# epi register map
Vendor: Texas Instruments
Peripheral module from a debugger description file (folder sc4ce290ncpz).
Registers are 32-bit, read-write, no defined reset value unless marked. A register's access mark holds for its fields unless they carry their own. Offsets are as the file gives them; lines under a group give offsets from that group; [hi:lo] are bit positions; {n}, {i} and the like mark numbered series; 'fields as' and 'values as' point back to an identical list; <NAME> marks a mode.

## EPI0 — External Peripheral Interface register offsets
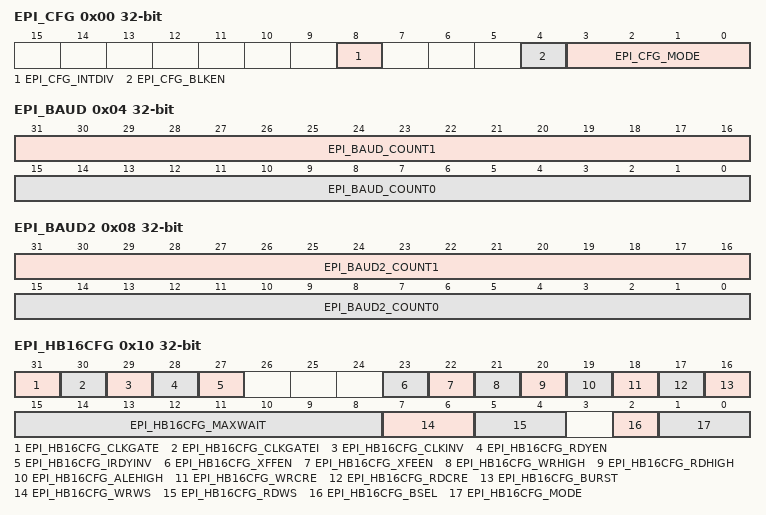
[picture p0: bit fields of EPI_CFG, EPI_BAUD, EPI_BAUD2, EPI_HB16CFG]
0x00 EPI_CFG — EPI Configuration
  [8] EPI_CFG_INTDIV — Integer Clock Divider Enable
  [4] EPI_CFG_BLKEN — Block Enable
  [3:0] EPI_CFG_MODE — Mode Select
    0=EPI_CFG_MODE_NONE (General Purpose); 1=EPI_CFG_MODE_SDRAM (SDRAM); 2=EPI_CFG_MODE_HB8 (8-Bit Host-Bus (HB8)); 3=EPI_CFG_MODE_HB16 (16-Bit Host-Bus (HB16))
0x04 EPI_BAUD — EPI Main Baud Rate
  [31:16] EPI_BAUD_COUNT1 — Baud Rate Counter 1
  [15:0] EPI_BAUD_COUNT0 — Baud Rate Counter 0
0x08 EPI_BAUD2 — EPI Main Baud Rate
  [31:16] EPI_BAUD2_COUNT1 — CS3n Baud Rate Counter 1
  [15:0] EPI_BAUD2_COUNT0 — CS2n Baud Rate Counter 0
0x10 EPI_HB16CFG — EPI Host-Bus 16 Configuration
  [31] EPI_HB16CFG_CLKGATE — Clock Gated
  [30] EPI_HB16CFG_CLKGATEI — Clock Gated Idle
  [29] EPI_HB16CFG_CLKINV — Invert Output Clock Enable
  [28] EPI_HB16CFG_RDYEN — Input Ready Enable
  [27] EPI_HB16CFG_IRDYINV — Input Ready Invert
  [23] EPI_HB16CFG_XFFEN — External FIFO FULL Enable
  [22] EPI_HB16CFG_XFEEN — External FIFO EMPTY Enable
  [21] EPI_HB16CFG_WRHIGH — WRITE Strobe Polarity
  [20] EPI_HB16CFG_RDHIGH — READ Strobe Polarity
  [19] EPI_HB16CFG_ALEHIGH — ALE Strobe Polarity
  [18] EPI_HB16CFG_WRCRE — PSRAM Configuration Register Write
  [17] EPI_HB16CFG_RDCRE — PSRAM Configuration Register Read
  [16] EPI_HB16CFG_BURST — Burst Mode
  [15:8] EPI_HB16CFG_MAXWAIT — Maximum Wait
  [7:6] EPI_HB16CFG_WRWS — Write Wait States
    0=Active WRn is 2 EPI clocks; 1=Active WRn is 4 EPI clocks; 2=Active WRn is 6 EPI clocks; 3=Active WRn is 8 EPI clocks
  [5:4] EPI_HB16CFG_RDWS — Read Wait States
    0=Active RDn is 2 EPI clocks; 1=Active RDn is 4 EPI clocks; 2=Active RDn is 6 EPI clocks; 3=Active RDn is 8 EPI clocks
  [2] EPI_HB16CFG_BSEL — Byte Select Configuration
  [1:0] EPI_HB16CFG_MODE — Host Bus Sub-Mode
    0=EPI_HB16CFG_MODE_ADMUX (ADMUX - AD[15:0]); 1=EPI_HB16CFG_MODE_ADNMUX (ADNONMUX - D[15:0]); 2=EPI_HB16CFG_MODE_SRAM (Continuous Read - D[15:0]); 3=EPI_HB16CFG_MODE_XFIFO (XFIFO - D[15:0])
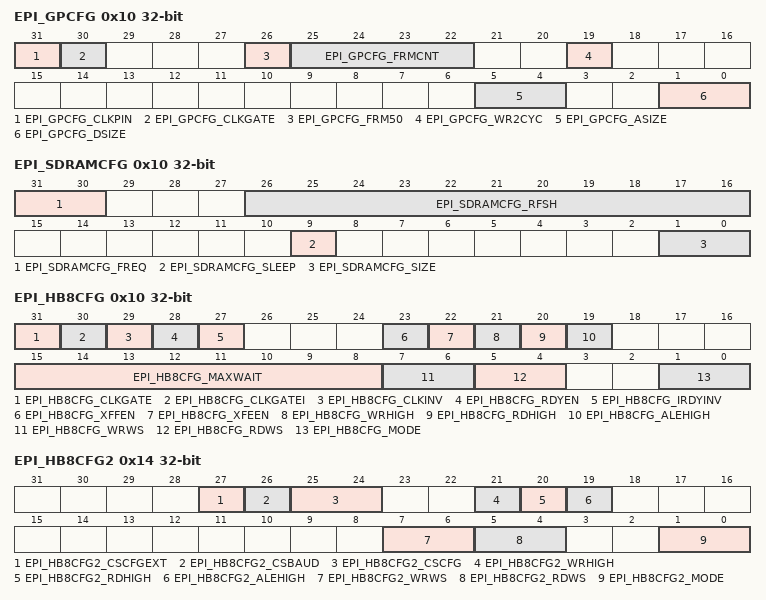
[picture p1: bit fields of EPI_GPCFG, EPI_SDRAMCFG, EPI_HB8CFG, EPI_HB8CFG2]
0x10 EPI_GPCFG — EPI General-Purpose Configuration
  [31] EPI_GPCFG_CLKPIN — Clock Pin
  [30] EPI_GPCFG_CLKGATE — Clock Gated
  [26] EPI_GPCFG_FRM50 — 50/50 Frame
  [25:22] EPI_GPCFG_FRMCNT — Frame Count
  [19] EPI_GPCFG_WR2CYC — 2-Cycle Writes
  [5:4] EPI_GPCFG_ASIZE — Address Bus Size
    0=EPI_GPCFG_ASIZE_NONE (No address); 1=EPI_GPCFG_ASIZE_4BIT (Up to 4 bits wide); 2=EPI_GPCFG_ASIZE_12BIT (Up to 12 bits wide. This size cannot be used with 24-bit data); 3=EPI_GPCFG_ASIZE_20BIT (Up to 20 bits wide. This size cannot be used with data sizes other than 8)
  [1:0] EPI_GPCFG_DSIZE — Size of Data Bus
    0=EPI_GPCFG_DSIZE_4BIT (8 Bits Wide (EPI0S0 to EPI0S7)); 1=EPI_GPCFG_DSIZE_16BIT (16 Bits Wide (EPI0S0 to EPI0S15)); 2=EPI_GPCFG_DSIZE_24BIT (24 Bits Wide (EPI0S0 to EPI0S23)); 3=EPI_GPCFG_DSIZE_32BIT (32 Bits Wide (EPI0S0 to EPI0S31))
0x10 EPI_SDRAMCFG — EPI SDRAM Configuration
  [31:30] EPI_SDRAMCFG_FREQ — EPI Frequency Range
    0=EPI_SDRAMCFG_FREQ_NONE (0 - 15 MHz); 1=EPI_SDRAMCFG_FREQ_15MHZ (15 - 30 MHz); 2=EPI_SDRAMCFG_FREQ_30MHZ (30 - 50 MHz)
  [26:16] EPI_SDRAMCFG_RFSH — Refresh Counter
  [9] EPI_SDRAMCFG_SLEEP — Sleep Mode
  [1:0] EPI_SDRAMCFG_SIZE — Size of SDRAM
    0=EPI_SDRAMCFG_SIZE_8MB (64 megabits (8MB)); 1=EPI_SDRAMCFG_SIZE_16MB (128 megabits (16MB)); 2=EPI_SDRAMCFG_SIZE_32MB (256 megabits (32MB)); 3=EPI_SDRAMCFG_SIZE_64MB (512 megabits (64MB))
0x10 EPI_HB8CFG — EPI Host-Bus 8 Configuration
  [31] EPI_HB8CFG_CLKGATE — Clock Gated
  [30] EPI_HB8CFG_CLKGATEI — Clock Gated when Idle
  [29] EPI_HB8CFG_CLKINV — Invert Output Clock Enable
  [28] EPI_HB8CFG_RDYEN — Input Ready Enable
  [27] EPI_HB8CFG_IRDYINV — Input Ready Invert
  [23] EPI_HB8CFG_XFFEN — External FIFO FULL Enable
  [22] EPI_HB8CFG_XFEEN — External FIFO EMPTY Enable
  [21] EPI_HB8CFG_WRHIGH — WRITE Strobe Polarity
  [20] EPI_HB8CFG_RDHIGH — READ Strobe Polarity
  [19] EPI_HB8CFG_ALEHIGH — ALE Strobe Polarity
  [15:8] EPI_HB8CFG_MAXWAIT — Maximum Wait
  [7:6] EPI_HB8CFG_WRWS — Write Wait States
    values as EPI_HB16CFG.EPI_HB16CFG_WRWS
  [5:4] EPI_HB8CFG_RDWS — Read Wait States
    values as EPI_HB16CFG.EPI_HB16CFG_RDWS
  [1:0] EPI_HB8CFG_MODE — Host Bus Sub-Mode
    0=EPI_HB8CFG_MODE_MUX (ADMUX - AD[7:0]); 1=EPI_HB8CFG_MODE_NMUX (ADNONMUX - D[7:0]); 2=EPI_HB8CFG_MODE_SRAM (Continuous Read - D[7:0]); 3=EPI_HB8CFG_MODE_FIFO (XFIFO - D[7:0])
0x14 EPI_HB8CFG2 — EPI Host-Bus 8 Configuration 2
  [27] EPI_HB8CFG2_CSCFGEXT — Chip Select Extended Configuration
  [26] EPI_HB8CFG2_CSBAUD — Chip Select Baud Rate and Multiple Sub-Mode Configuration enable
  [25:24] EPI_HB8CFG2_CSCFG — Chip Select Configuration
    0=EPI_HB8CFG2_CSCFG_ALE (ALE Configuration); 1=EPI_HB8CFG2_CSCFG_CS (CSn Configuration); 2=EPI_HB8CFG2_CSCFG_DCS (Dual CSn Configuration); 3=EPI_HB8CFG2_CSCFG_ADCS (ALE with Dual CSn Configuration)
  [21] EPI_HB8CFG2_WRHIGH — CS1n WRITE Strobe Polarity
  [20] EPI_HB8CFG2_RDHIGH — CS1n READ Strobe Polarity
  [19] EPI_HB8CFG2_ALEHIGH — CS1n ALE Strobe Polarity
  [7:6] EPI_HB8CFG2_WRWS — CS1n Write Wait States
    values as EPI_HB16CFG.EPI_HB16CFG_WRWS
  [5:4] EPI_HB8CFG2_RDWS — CS1n Read Wait States
    values as EPI_HB16CFG.EPI_HB16CFG_RDWS
  [1:0] EPI_HB8CFG2_MODE — CS1n Host Bus Sub-Mode
    0=EPI_HB8CFG2_MODE_ADMUX (ADMUX - AD[7:0]); 1=EPI_HB8CFG2_MODE_AD (ADNONMUX - D[7:0])
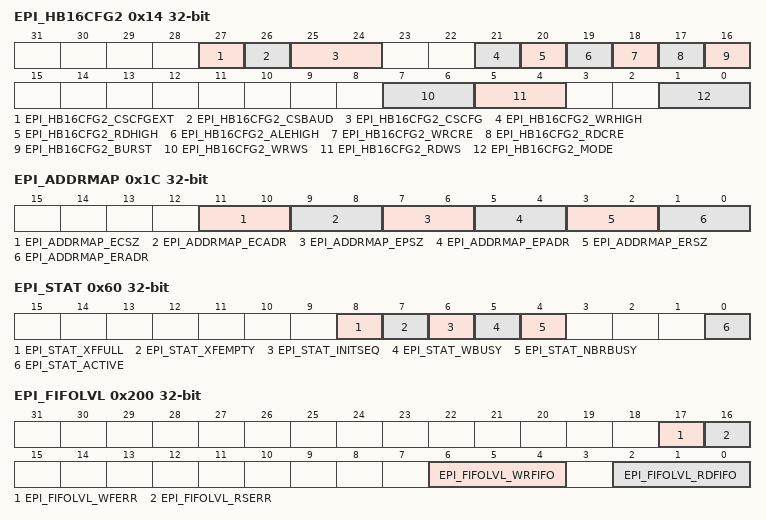
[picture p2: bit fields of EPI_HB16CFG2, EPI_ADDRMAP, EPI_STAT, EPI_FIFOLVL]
0x14 EPI_HB16CFG2 — EPI Host-Bus 16 Configuration 2
  [27] EPI_HB16CFG2_CSCFGEXT — Chip Select Extended Configuration
  [26] EPI_HB16CFG2_CSBAUD — Chip Select Baud Rate and Multiple Sub-Mode Configuration enable
  [25:24] EPI_HB16CFG2_CSCFG — Chip Select Configuration
    0=EPI_HB16CFG2_CSCFG_ALE (ALE Configuration); 1=EPI_HB16CFG2_CSCFG_CS (CSn Configuration); 2=EPI_HB16CFG2_CSCFG_DCS (Dual CSn Configuration); 3=EPI_HB16CFG2_CSCFG_ADCS (ALE with Dual CSn Configuration)
  [21] EPI_HB16CFG2_WRHIGH — CS1n WRITE Strobe Polarity
  [20] EPI_HB16CFG2_RDHIGH — CS1n READ Strobe Polarity
  [19] EPI_HB16CFG2_ALEHIGH — CS1n ALE Strobe Polarity
  [18] EPI_HB16CFG2_WRCRE — CS1n PSRAM Configuration Register Write
  [17] EPI_HB16CFG2_RDCRE — CS1n PSRAM Configuration Register Read
  [16] EPI_HB16CFG2_BURST — CS1n Burst Mode
  [7:6] EPI_HB16CFG2_WRWS — CS1n Write Wait States
    values as EPI_HB16CFG.EPI_HB16CFG_WRWS
  [5:4] EPI_HB16CFG2_RDWS — CS1n Read Wait States
    values as EPI_HB16CFG.EPI_HB16CFG_RDWS
  [1:0] EPI_HB16CFG2_MODE — CS1n Host Bus Sub-Mode
    0=EPI_HB16CFG2_MODE_ADMUX (ADMUX - AD[15:0]); 1=EPI_HB16CFG2_MODE_AD (ADNONMUX - D[15:0])
0x1C EPI_ADDRMAP — EPI Address Map
  [11:10] EPI_ADDRMAP_ECSZ — External Code Size
    0=EPI_ADDRMAP_ECSZ_256B (256 bytes; lower address range: 0x00 to 0xFF); 1=EPI_ADDRMAP_ECSZ_64KB (64 KB; lower address range: 0x0000 to 0xFFFF); 2=EPI_ADDRMAP_ECSZ_16MB (16 MB; lower address range: 0x00.0000 to 0xFF.FFFF); 3=EPI_ADDRMAP_ECSZ_256MB (256MB; lower address range: 0x000.0000 to 0x0FFF.FFFF)
  [9:8] EPI_ADDRMAP_ECADR — External Code Address
    0=EPI_ADDRMAP_ECADR_NONE (Not mapped); 1=At 0x1000.0000
  [7:6] EPI_ADDRMAP_EPSZ — External Peripheral Size
    0=EPI_ADDRMAP_EPSZ_256B (256 bytes; lower address range: 0x00 to 0xFF); 1=EPI_ADDRMAP_EPSZ_64KB (64 KB; lower address range: 0x0000 to 0xFFFF); 2=EPI_ADDRMAP_EPSZ_16MB (16 MB; lower address range: 0x00.0000 to 0xFF.FFFF); 3=EPI_ADDRMAP_EPSZ_256MB (256 MB; lower address range: 0x000.0000 to 0xFFF.FFFF)
  [5:4] EPI_ADDRMAP_EPADR — External Peripheral Address
    0=EPI_ADDRMAP_EPADR_NONE (Not mapped); 1=EPI_ADDRMAP_EPADR_A000 (At 0xA000.0000); 2=EPI_ADDRMAP_EPADR_C000 (At 0xC000.0000); 3=EPI_ADDRMAP_EPADR_HBQS (Only to be used with Host Bus quad chip select. In quad chip select mode, CS2n maps to 0xA000.0000 and CS3n maps to 0xC000.0000)
  [3:2] EPI_ADDRMAP_ERSZ — External RAM Size
    0=EPI_ADDRMAP_ERSZ_256B (256 bytes; lower address range: 0x00 to 0xFF); 1=EPI_ADDRMAP_ERSZ_64KB (64 KB; lower address range: 0x0000 to 0xFFFF); 2=EPI_ADDRMAP_ERSZ_16MB (16 MB; lower address range: 0x00.0000 to 0xFF.FFFF); 3=EPI_ADDRMAP_ERSZ_256MB (256 MB; lower address range: 0x000.0000 to 0xFFF.FFFF)
  [1:0] EPI_ADDRMAP_ERADR — External RAM Address
    0=EPI_ADDRMAP_ERADR_NONE (Not mapped); 1=At 0x6000.0000; 2=At 0x8000.0000; 3=EPI_ADDRMAP_ERADR_HBQS (Only to be used with Host Bus quad chip select. In quad chip select mode, CS0n maps to 0x6000.0000 and CS1n maps to 0x8000.0000)
0x20 EPI_RSIZE0 — EPI Read Size 0
  [1:0] EPI_RSIZE0_SIZE — Current Size
    1=EPI_RSIZE0_SIZE_8BIT (Byte (8 bits)); 2=EPI_RSIZE0_SIZE_16BIT (Half-word (16 bits)); 3=EPI_RSIZE0_SIZE_32BIT (Word (32 bits))
0x24 EPI_RADDR0 — EPI Read Address 0
  [31:0] EPI_RADDR0_ADDR — Current Address
0x28 EPI_RPSTD0 — EPI Non-Blocking Read Data 0
  [12:0] EPI_RPSTD0_POSTCNT — Post Count
0x30 EPI_RSIZE1 — EPI Read Size 1
  [1:0] EPI_RSIZE1_SIZE — Current Size
    1=EPI_RSIZE1_SIZE_8BIT (Byte (8 bits)); 2=EPI_RSIZE1_SIZE_16BIT (Half-word (16 bits)); 3=EPI_RSIZE1_SIZE_32BIT (Word (32 bits))
0x34 EPI_RADDR1 — EPI Read Address 1
  [31:0] EPI_RADDR1_ADDR — Current Address
0x38 EPI_RPSTD1 — EPI Non-Blocking Read Data 1
  [12:0] EPI_RPSTD1_POSTCNT — Post Count
0x60 EPI_STAT ro — EPI Status
  [8] EPI_STAT_XFFULL — External FIFO Full
  [7] EPI_STAT_XFEMPTY — External FIFO Empty
  [6] EPI_STAT_INITSEQ — Initialization Sequence
  [5] EPI_STAT_WBUSY — Write Busy
  [4] EPI_STAT_NBRBUSY — Non-Blocking Read Busy
  [0] EPI_STAT_ACTIVE — Register Active
0x6C EPI_RFIFOCNT ro — EPI Read FIFO Count
  [3:0] EPI_RFIFOCNT_COUNT — FIFO Count
0x70 EPI_READFIFO0 ro — EPI Read FIFO
  [31:0] EPI_READFIFO0_DATA — Reads Data
{0x70+4i} EPI_READFIFO{i} ro (i=1..7) — EPI Read FIFO Alias {i}
  [31:0] EPI_READFIFO{i}_DATA — Reads Data
0x200 EPI_FIFOLVL — EPI FIFO Level Selects
  [17] EPI_FIFOLVL_WFERR — Write Full Error
  [16] EPI_FIFOLVL_RSERR — Read Stall Error
  [6:4] EPI_FIFOLVL_WRFIFO — Write FIFO
    0=EPI_FIFOLVL_WRFIFO_EMPT (Interrupt is triggered while WRFIFO is empty.); 2=Interrupt is triggered until there are only two slots available. Thus, trigger is deasserted when there are two WRFIFO entries present. This configuration is optimized for bursts of 2; 3=Interrupt is triggered until there is one WRFIFO entry available. This configuration expects only single writes; 4=EPI_FIFOLVL_WRFIFO_NFULL (Trigger interrupt when WRFIFO is not full, meaning trigger will continue to assert until there are four entries in the WRFIFO)
  [2:0] EPI_FIFOLVL_RDFIFO — Read FIFO
    1=Trigger when there are 1 or more entries in the NBRFIFO; 2=Trigger when there are 2 or more entries in the NBRFIFO; 3=Trigger when there are 4 or more entries in the NBRFIFO; 4=Trigger when there are 6 or more entries in the NBRFIFO; 5=Trigger when there are 7 or more entries in the NBRFIFO; 6=Trigger when there are 8 entries in the NBRFIFO
0x204 EPI_WFIFOCNT ro — EPI Write FIFO Count
  [2:0] EPI_WFIFOCNT_WTAV — Available Write Transactions
0x208 EPI_DMATXCNT — EPI DMA Transmit Count
  [15:0] EPI_DMATXCNT_TXCNT — DMA Count
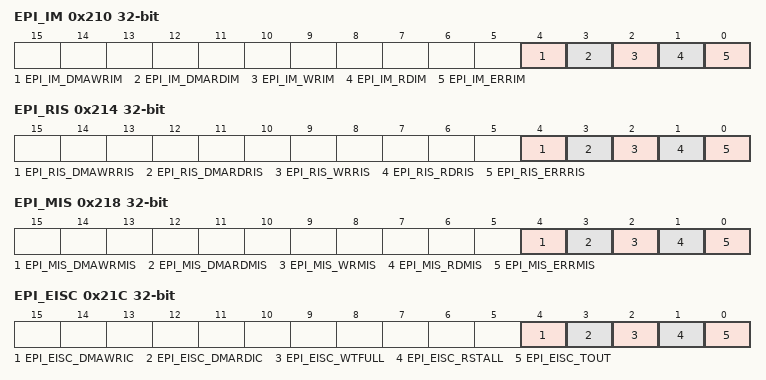
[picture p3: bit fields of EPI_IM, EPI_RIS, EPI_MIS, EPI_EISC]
0x210 EPI_IM — EPI Interrupt Mask
  [4] EPI_IM_DMAWRIM — Write uDMA Interrupt Mask
  [3] EPI_IM_DMARDIM — Read uDMA Interrupt Mask
  [2] EPI_IM_WRIM — Write FIFO Empty Interrupt Mask
  [1] EPI_IM_RDIM — Read FIFO Full Interrupt Mask
  [0] EPI_IM_ERRIM — Error Interrupt Mask
0x214 EPI_RIS ro — EPI Raw Interrupt Status
  [4] EPI_RIS_DMAWRRIS — Write uDMA Raw Interrupt Status
  [3] EPI_RIS_DMARDRIS — Read uDMA Raw Interrupt Status
  [2] EPI_RIS_WRRIS — Write Raw Interrupt Status
  [1] EPI_RIS_RDRIS — Read Raw Interrupt Status
  [0] EPI_RIS_ERRRIS — Error Raw Interrupt Status
0x218 EPI_MIS ro — EPI Masked Interrupt Status
  [4] EPI_MIS_DMAWRMIS — Write uDMA Masked Interrupt Status
  [3] EPI_MIS_DMARDMIS — Read uDMA Masked Interrupt Status
  [2] EPI_MIS_WRMIS — Write Masked Interrupt Status
  [1] EPI_MIS_RDMIS — Read Masked Interrupt Status
  [0] EPI_MIS_ERRMIS — Error Masked Interrupt Status
0x21C EPI_EISC — EPI Error and Interrupt Status and Clear
  [4] EPI_EISC_DMAWRIC — Write uDMA Interrupt Clear
  [3] EPI_EISC_DMARDIC — Read uDMA Interrupt Clear
  [2] EPI_EISC_WTFULL — Write FIFO Full Error
  [1] EPI_EISC_RSTALL — Read Stalled Error
  [0] EPI_EISC_TOUT — Timeout Error
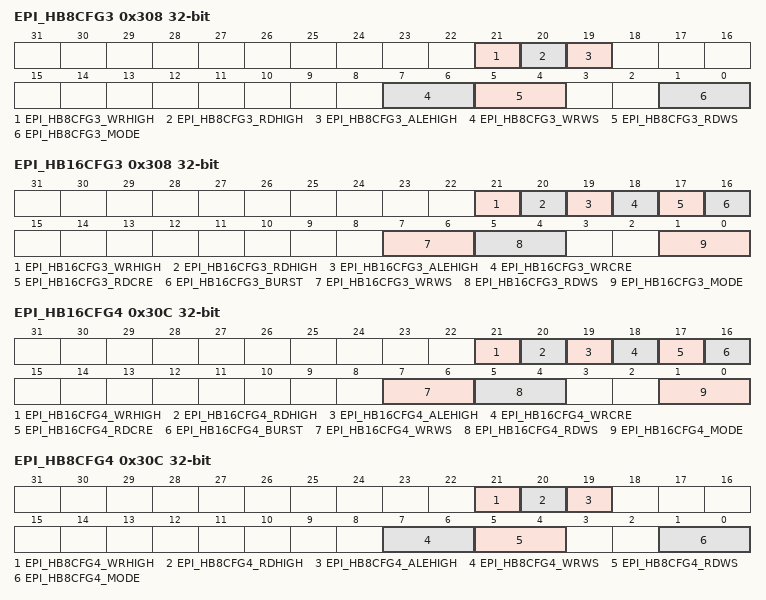
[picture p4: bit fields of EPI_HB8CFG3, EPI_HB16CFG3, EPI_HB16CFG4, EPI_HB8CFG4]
0x308 EPI_HB8CFG3 — EPI Host-Bus 8 Configuration 3
  [21] EPI_HB8CFG3_WRHIGH — CS2n WRITE Strobe Polarity
  [20] EPI_HB8CFG3_RDHIGH — CS2n READ Strobe Polarity
  [19] EPI_HB8CFG3_ALEHIGH — CS2n ALE Strobe Polarity
  [7:6] EPI_HB8CFG3_WRWS — CS2n Write Wait States
    values as EPI_HB16CFG.EPI_HB16CFG_WRWS
  [5:4] EPI_HB8CFG3_RDWS — CS2n Read Wait States
    values as EPI_HB16CFG.EPI_HB16CFG_RDWS
  [1:0] EPI_HB8CFG3_MODE — CS2n Host Bus Sub-Mode
    0=EPI_HB8CFG3_MODE_ADMUX (ADMUX - AD[7:0]); 1=EPI_HB8CFG3_MODE_AD (ADNONMUX - D[7:0])
0x308 EPI_HB16CFG3 — EPI Host-Bus 16 Configuration 3
  [21] EPI_HB16CFG3_WRHIGH — CS2n WRITE Strobe Polarity
  [20] EPI_HB16CFG3_RDHIGH — CS2n READ Strobe Polarity
  [19] EPI_HB16CFG3_ALEHIGH — CS2n ALE Strobe Polarity
  [18] EPI_HB16CFG3_WRCRE — CS2n PSRAM Configuration Register Write
  [17] EPI_HB16CFG3_RDCRE — CS2n PSRAM Configuration Register Read
  [16] EPI_HB16CFG3_BURST — CS2n Burst Mode
  [7:6] EPI_HB16CFG3_WRWS — CS2n Write Wait States
    values as EPI_HB16CFG.EPI_HB16CFG_WRWS
  [5:4] EPI_HB16CFG3_RDWS — CS2n Read Wait States
    values as EPI_HB16CFG.EPI_HB16CFG_RDWS
  [1:0] EPI_HB16CFG3_MODE — CS2n Host Bus Sub-Mode
    0=EPI_HB16CFG3_MODE_ADMUX (ADMUX - AD[15:0]); 1=EPI_HB16CFG3_MODE_AD (ADNONMUX - D[15:0])
0x30C EPI_HB16CFG4 — EPI Host-Bus 16 Configuration 4
  [21] EPI_HB16CFG4_WRHIGH — CS3n WRITE Strobe Polarity
  [20] EPI_HB16CFG4_RDHIGH — CS3n READ Strobe Polarity
  [19] EPI_HB16CFG4_ALEHIGH — CS3n ALE Strobe Polarity
  [18] EPI_HB16CFG4_WRCRE — CS3n PSRAM Configuration Register Write
  [17] EPI_HB16CFG4_RDCRE — CS3n PSRAM Configuration Register Read
  [16] EPI_HB16CFG4_BURST — CS3n Burst Mode
  [7:6] EPI_HB16CFG4_WRWS — CS3n Write Wait States
    values as EPI_HB16CFG.EPI_HB16CFG_WRWS
  [5:4] EPI_HB16CFG4_RDWS — CS3n Read Wait States
    values as EPI_HB16CFG.EPI_HB16CFG_RDWS
  [1:0] EPI_HB16CFG4_MODE — CS3n Host Bus Sub-Mode
    0=EPI_HB16CFG4_MODE_ADMUX (ADMUX - AD[15:0]); 1=EPI_HB16CFG4_MODE_AD (ADNONMUX - D[15:0])
0x30C EPI_HB8CFG4 — EPI Host-Bus 8 Configuration 4
  [21] EPI_HB8CFG4_WRHIGH — CS3n WRITE Strobe Polarity
  [20] EPI_HB8CFG4_RDHIGH — CS2n READ Strobe Polarity
  [19] EPI_HB8CFG4_ALEHIGH — CS3n ALE Strobe Polarity
  [7:6] EPI_HB8CFG4_WRWS — CS3n Write Wait States
    values as EPI_HB16CFG.EPI_HB16CFG_WRWS
  [5:4] EPI_HB8CFG4_RDWS — CS3n Read Wait States
    values as EPI_HB16CFG.EPI_HB16CFG_RDWS
  [1:0] EPI_HB8CFG4_MODE — CS3n Host Bus Sub-Mode
    0=EPI_HB8CFG4_MODE_ADMUX (ADMUX - AD[7:0]); 1=EPI_HB8CFG4_MODE_AD (ADNONMUX - D[7:0])
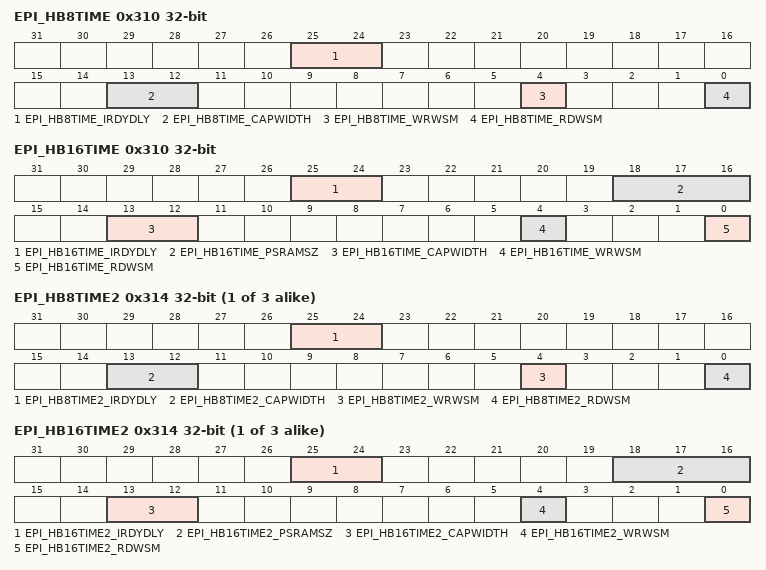
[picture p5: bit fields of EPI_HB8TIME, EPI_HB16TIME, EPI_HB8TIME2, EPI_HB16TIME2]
0x310 EPI_HB8TIME — EPI Host-Bus 8 Timing Extension
  [25:24] EPI_HB8TIME_IRDYDLY — CS0n Input Ready Delay
  [13:12] EPI_HB8TIME_CAPWIDTH — CS0n Inter-transfer Capture Width
  [4] EPI_HB8TIME_WRWSM — Write Wait State Minus One
  [0] EPI_HB8TIME_RDWSM — Read Wait State Minus One
0x310 EPI_HB16TIME — EPI Host-Bus 16 Timing Extension
  [25:24] EPI_HB16TIME_IRDYDLY — CS0n Input Ready Delay
  [18:16] EPI_HB16TIME_PSRAMSZ — PSRAM Row Size
    0=No row size limitation; 1=EPI_HB16TIME_PSRAMSZ_128B (128 B); 2=EPI_HB16TIME_PSRAMSZ_256B (256 B); 3=EPI_HB16TIME_PSRAMSZ_512B (512 B); 4=EPI_HB16TIME_PSRAMSZ_1KB (1024 B); 5=EPI_HB16TIME_PSRAMSZ_2KB (2048 B); 6=EPI_HB16TIME_PSRAMSZ_4KB (4096 B); 7=EPI_HB16TIME_PSRAMSZ_8KB (8192 B)
  [13:12] EPI_HB16TIME_CAPWIDTH — CS0n Inter-transfer Capture Width
  [4] EPI_HB16TIME_WRWSM — Write Wait State Minus One
  [0] EPI_HB16TIME_RDWSM — Read Wait State Minus One
{0x30C+4i} EPI_HB8TIME{i} (i=2..4) — EPI Host-Bus 8 Timing Extension
  [25:24] EPI_HB8TIME{i}_IRDYDLY — CS{i-1}n Input Ready Delay
  [13:12] EPI_HB8TIME{i}_CAPWIDTH — CS{i-1}n Inter-transfer Capture Width
  [4] EPI_HB8TIME{i}_WRWSM — CS{i-1}n Write Wait State Minus One
  [0] EPI_HB8TIME{i}_RDWSM — CS{i-1}n Read Wait State Minus One
{0x30C+4i} EPI_HB16TIME{i} (i=2..4) — EPI Host-Bus 16 Timing Extension
  [25:24] EPI_HB16TIME{i}_IRDYDLY — CS{i-1}n Input Ready Delay
  [18:16] EPI_HB16TIME{i}_PSRAMSZ — PSRAM Row Size
    0=No row size limitation; 1=EPI_HB16TIME{i}_PSRAMSZ_128B (128 B); 2=EPI_HB16TIME{i}_PSRAMSZ_256B (256 B); 3=EPI_HB16TIME{i}_PSRAMSZ_512B (512 B); 4=EPI_HB16TIME{i}_PSRAMSZ_1KB (1024 B); 5=EPI_HB16TIME{i}_PSRAMSZ_2KB (2048 B); 6=EPI_HB16TIME{i}_PSRAMSZ_4KB (4096 B); 7=EPI_HB16TIME{i}_PSRAMSZ_8KB (8192 B)
  [13:12] EPI_HB16TIME{i}_CAPWIDTH — CS{i-1}n Inter-transfer Capture Width
  [4] EPI_HB16TIME{i}_WRWSM — CS{i-1}n Write Wait State Minus One
  [0] EPI_HB16TIME{i}_RDWSM — CS{i-1}n Read Wait State Minus One
0x360 EPI_HBPSRAM — EPI Host-Bus PSRAM
  [20:0] EPI_HBPSRAM_CR — PSRAM Config Register
